AUTOSAR XML (schema 4-2-2)
standard types defined: uint16
package /PortInterfaces
  sender receiver interface VehicleSpeed_I
    data VehicleSpeed: type=uint16
package /ComponentTypes
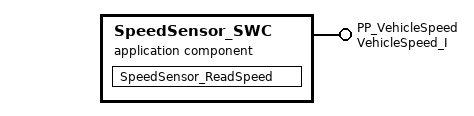
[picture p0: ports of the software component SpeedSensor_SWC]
  application sw component type SpeedSensor_SWC
    provide port PP_VehicleSpeed: provided-interface=VehicleSpeed_I
    behavior SpeedSensor_InternalBehavior
      timing event TE_20ms: period=0.02, start-on-event=SpeedSensor_ReadSpeed
      runnable SpeedSensor_ReadSpeed
        data-write-access:
          access DWA_VehicleSpeed: accessed-variable=PP_VehicleSpeed.VehicleSpeed
